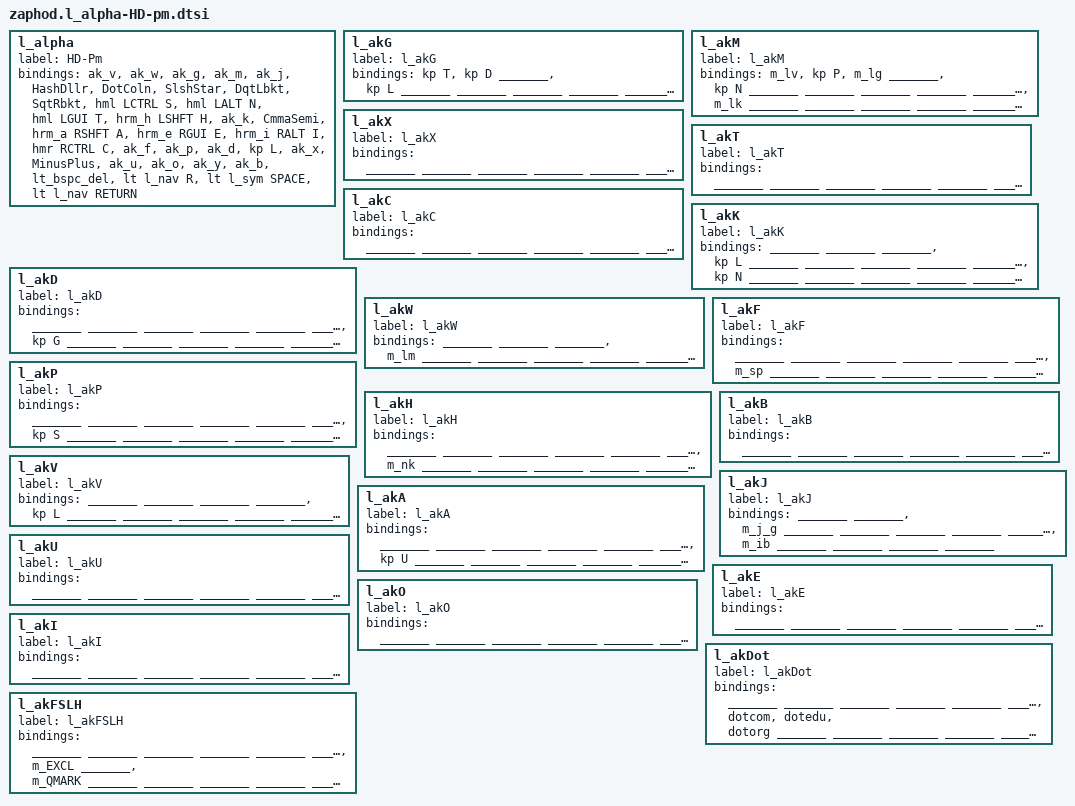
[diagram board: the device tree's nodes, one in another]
#define _______  &trans

/*  Base (alpha) Layer  Hands Down Promethium-pm
        for 36 keys on a board with 34 keys
╭─────────────────────╮ ╭──────────────────────╮
│  V   W   G   M   J  │ │  #$  .:  /*  "[  ']  │
│  S   N   T   H   K  | |  ,;   A   E   I   C  │
│  F   P   D   L   X  │ │  -+   U   O   Y   B  │
╰────╮        BSP  R  │ │  SPC RET        ╭────╯
     ╰────────────────╯ ╰─────────────────╯
*/

                    l_alpha {
                        label = "HD-Pm";
                        bindings = <
&ak_v    &ak_w      &ak_g     &ak_m     &ak_j         &HashDllr  &DotColn  &SlshStar &DqtLbkt &SqtRbkt
&hml LCTRL S &hml LALT N   &hml LGUI T  &hrm_h LSHFT H &ak_k     &CmmaSemi &hrm_a RSHFT A &hrm_e RGUI E  &hrm_i RALT I  &hmr RCTRL C
&ak_f    &ak_p      &ak_d     &kp L     &ak_x         &MinusPlus &ak_u     &ak_o     &ak_y    &ak_b
                        &lt_bspc_del &lt l_nav R      &lt l_sym SPACE &lt l_nav RETURN
                        >;
                    };
                    l_akG {
                        label = "l_akG";
                        bindings = <
&kp T     &kp D     _______   &kp L     _______       _______   _______   _______   _______   _______
_______   _______   _______   _______   _______       _______   _______   _______   _______   _______
_______   _______   _______   _______   _______       _______   _______   _______   _______   _______
                              _______   _______       _______   _______
                            >;
                    };
                    l_akM {
                        label = "l_akM";
                        bindings = <
&m_lv     &kp P     &m_lg     _______   &kp N         _______   _______   _______   _______   _______
_______   _______   _______   _______   &m_lk         _______   _______   _______   _______   _______
_______   _______   _______   _______   _______       _______   _______   _______   _______   _______
                              _______   _______       _______   _______
                        >;
                    };
                    l_akX {
                        label = "l_akX";
                        bindings = <
_______   _______   _______   _______   _______       _______   _______   _______   _______   _______
_______   _______   _______   _______   _______       _______   _______   _______   _______   _______
_______   _______   _______   _______   _______       _______   _______   _______   _______   _______
                              _______   _______       _______   _______
                        >;
                    };
                    l_akT {
                        label = "l_akT";
                        bindings = <
_______   _______   _______   _______   _______       _______   _______   _______   _______   _______
_______   _______   _______   _______   _______       _______   _______   _______   _______   _______
_______   _______   _______   _______   _______       _______   _______   _______   _______   _______
                              _______   _______       _______   _______
                            >;
                    };
                    l_akC {
                    label = "l_akC";
                    bindings = <
_______   _______   _______   _______   _______       _______   _______   _______   _______   _______
_______   _______   _______   _______   _______       _______   _______   _______   _______   _______
_______   _______   _______   _______   _______       _______   _______   _______   _______   _______
                              _______   _______       _______   _______
                        >;
                    };
                    l_akK {
                        label = "l_akK";
                        bindings = <
_______   _______   _______   &kp L     _______       _______   _______   _______   _______   _______
_______   _______   _______   &kp N     _______       _______   _______   _______   _______   _______
_______   _______   _______   _______   _______       _______   _______   _______   _______   _______
                              _______   _______       _______   _______
                            >;
                    };
                    l_akD {
                        label = "l_akD";
                        bindings = <
_______   _______   _______   _______   _______       _______   _______   _______   _______   _______
_______   _______   _______   _______   _______       _______   _______   _______   _______   _______
_______   &kp G     _______   _______   _______       _______   _______   _______   _______   _______
                              _______   _______       _______   _______
                            >;
                    };
                    l_akW {
                        label = "l_akW";
                        bindings = <
_______   _______   _______   &m_lm     _______       _______   _______   _______   _______   _______
_______   _______   _______   _______   _______       _______   _______   _______   _______   _______
_______   _______   _______   _______   _______       _______   _______   _______   _______   _______
                              _______   _______       _______   _______
                        >;
                    };
                    l_akF {
                        label = "l_akF";
                        bindings = <
_______   _______   _______   _______   _______       _______   _______   _______   _______   _______
_______   _______   _______   _______   _______       _______   _______   _______   _______   _______
_______   &m_sp     _______   _______   _______       _______   _______   _______   _______   _______
                              _______   _______       _______   _______
                            >;
                    };
                    l_akP {
                        label = "l_akP";
                        bindings = <
_______   _______   _______   _______   _______       _______   _______   _______   _______   _______
_______   _______   _______   _______   _______       _______   _______   _______   _______   _______
&kp S     _______   _______   _______   _______       _______   _______   _______   _______   _______
                              _______   _______       _______   _______
                            >;
                    };
                    l_akH {
                        label = "l_akH";
                        bindings = <
_______   _______   _______   _______   _______       _______   _______   _______   _______   _______
_______   _______   _______   _______   &m_nk         _______   _______   _______   _______   _______
_______   _______   _______   _______   _______       _______   _______   _______   _______   _______
                              _______   _______       _______   _______
                            >;
                    };
                    l_akB {
                        label = "l_akB";
                        bindings = <
_______   _______   _______   _______   _______       _______   _______   _______   _______   _______
_______   _______   _______   _______   _______       _______   _______   _______   _______   _______
_______   _______   _______   _______   _______       _______   _______   _______   _______   _______
                              _______   _______       _______   _______
                            >;
                    };
                    l_akV {
                        label = "l_akV";
                        bindings = <
_______   _______   _______   _______   &kp L         _______   _______   _______   _______   _______
_______   _______   _______   _______   _______       _______   _______   _______   _______   _______
_______   _______   _______   _______   _______       _______   _______   _______   _______   _______
                              _______   _______       _______   _______
                        >;
                    };
                    l_akJ {
                        label = "l_akJ";
                        bindings = <
_______   _______   &m_j_g    _______   _______       _______   _______   _______   _______   _______
_______   _______   _______   _______   _______       _______   _______   _______   _______   _______
_______   _______   _______   _______   _______       _______   _______   _______   _______   &m_ib
                              _______   _______       _______   _______
                        >;
                    };


                    l_akA {
                        label = "l_akA";
                        bindings = <
_______   _______   _______   _______   _______       _______   _______   _______   _______   _______
_______   _______   _______   _______   _______       _______   _______   &kp U     _______   _______
_______   _______   _______   _______   _______       _______   _______   _______   _______   _______
                              _______   _______       _______   _______
                        >;
                    };
                    l_akU {
                        label = "l_akU";
                        bindings = <
_______   _______   _______   _______   _______       _______   _______   _______   _______   _______
_______   _______   _______   _______   _______       _______   _______   _______   _______   _______
_______   _______   _______   _______   _______       _______   _______   _______   _______   _______
                              _______   _______       _______   _______
                            >;
                    };
                   l_akE {
                        label = "l_akE";
                        bindings = <
_______   _______   _______   _______   _______       _______   _______   _______   _______   _______
_______   _______   _______   _______   _______       _______   _______   _______   _______   _______
_______   _______   _______   _______   _______       _______   _______   _______   _______   _______
                              _______   _______       _______   _______
                            >;
                   };
                   l_akO {
                        label = "l_akO";
                        bindings = <
_______   _______   _______   _______   _______       _______   _______   _______   _______   _______
_______   _______   _______   _______   _______       _______   _______   _______   _______   _______
_______   _______   _______   _______   _______       _______   _______   _______   _______   _______
                              _______   _______       _______   _______
                            >;
                   };
                   l_akI {
                        label = "l_akI";
                            bindings = <
_______   _______   _______   _______   _______       _______   _______   _______   _______   _______
_______   _______   _______   _______   _______       _______   _______   _______   _______   _______
_______   _______   _______   _______   _______       _______   _______   _______   _______   _______
                              _______   _______       _______   _______
                        >;
                   };

                   l_akDot {
                        label = "l_akDot";
                        bindings = <
_______   _______   _______   _______   _______       _______   _______   &dotcom   &dotedu   &dotorg
_______   _______   _______   _______   _______       _______   _______   _______   _______   _______
_______   _______   _______   _______   _______       _______   _______   _______   _______   _______
                              _______   _______       _______   _______
                            >;
                   };
                l_akFSLH {
                        label = "l_akFSLH";
                        bindings = <

_______   _______   _______   _______   _______       _______   &m_EXCL   _______  &m_QMARK   _______
_______   _______   _______   _______   _______       _______   _______   _______   _______   _______
_______   _______   _______   _______   _______       _______   _______   _______   _______   _______
                              _______   _______       _______   _______
                        >;
                };
